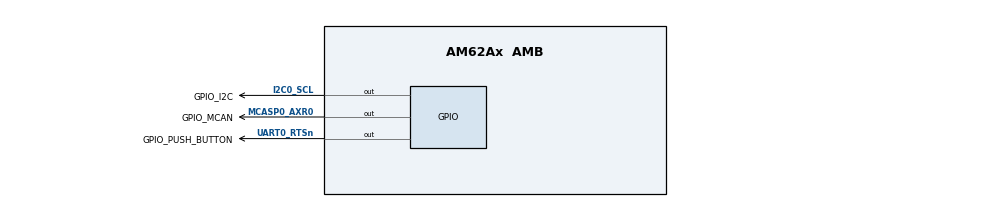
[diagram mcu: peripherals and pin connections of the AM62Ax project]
/**
 * @cliArgs --device "AM62Ax" --part "Default" --package "AMB" --context "mcu-r5fss0-0" --product "MCU_PLUS_SDK@07.03.01"
 * @versions {"tool":"1.26.2+4477"}
 */

/**
 * Import the modules used in this configuration.
 */
const gpio       = scripting.addModule("/drivers/gpio/gpio", {}, false);
const gpio1      = gpio.addInstance();
const gpio2      = gpio.addInstance();
const gpio3      = gpio.addInstance();
const gpio4      = gpio.addInstance();
const gpio5      = gpio.addInstance();
const gpio6      = gpio.addInstance();
const gpio7      = gpio.addInstance();
const gpio8      = gpio.addInstance();
const gpio9      = gpio.addInstance();
const gpio10     = gpio.addInstance();
const debug_log  = scripting.addModule("/kernel/dpl/debug_log");
const mpu_armv7  = scripting.addModule("/kernel/dpl/mpu_armv7", {}, false);
const mpu_armv71 = mpu_armv7.addInstance();
const mpu_armv72 = mpu_armv7.addInstance();
const mpu_armv73 = mpu_armv7.addInstance();
const mpu_armv74 = mpu_armv7.addInstance();
const mpu_armv75 = mpu_armv7.addInstance();
const mpu_armv76 = mpu_armv7.addInstance();

/**
 * Write custom configuration values to the imported modules.
 */
gpio1.$name  = "GPIO_LED";
gpio1.pinDir = "OUTPUT";

gpio2.$name                   = "GPIO_PUSH_BUTTON";
gpio2.trigType                = "RISE_EDGE";
gpio2.useMcuDomainPeripherals = false;
gpio2.GPIO.gpioPin.$assign    = "UART0_RTSn";

gpio3.$name                   = "GPIO_I2C";
gpio3.pinDir                  = "OUTPUT";
gpio3.trigType                = "FALL_EDGE";
gpio3.useMcuDomainPeripherals = false;
gpio3.GPIO.gpioPin.$assign    = "I2C0_SCL";

gpio4.$name                   = "GPIO_MCAN";
gpio4.pinDir                  = "OUTPUT";
gpio4.trigType                = "BOTH_EDGE";
gpio4.useMcuDomainPeripherals = false;
gpio4.GPIO.gpioPin.$assign    = "MCASP0_AXR0";

gpio5.$name    = "GPIO_OSPI_D1";
gpio5.pinDir   = "OUTPUT";
gpio5.trigType = "RISE_EDGE";

gpio6.$name    = "GPIO_OSPI_D2";
gpio6.pinDir   = "OUTPUT";
gpio6.trigType = "FALL_EDGE";

gpio7.$name    = "GPIO_INPUT";
gpio7.trigType = "RISE_EDGE";

gpio8.$name    = "GPIO_OUTPUT";
gpio8.pinDir   = "OUTPUT";
gpio8.trigType = "RISE_EDGE";

gpio9.$name = "CONFIG_GPIO0";

gpio10.$name = "CONFIG_GPIO1";

debug_log.enableUartLog = true;
debug_log.uartLog.$name = "CONFIG_UART0";

mpu_armv71.$name             = "CONFIG_MPU_REGION0";
mpu_armv71.size              = 31;
mpu_armv71.attributes        = "Device";
mpu_armv71.accessPermissions = "Supervisor RD+WR, User RD";
mpu_armv71.allowExecute      = false;

mpu_armv72.$name             = "CONFIG_MPU_REGION1";
mpu_armv72.size              = 15;
mpu_armv72.accessPermissions = "Supervisor RD+WR, User RD";

mpu_armv73.$name             = "CONFIG_MPU_REGION2";
mpu_armv73.baseAddr          = 0x41010000;
mpu_armv73.size              = 15;
mpu_armv73.accessPermissions = "Supervisor RD+WR, User RD";

mpu_armv74.$name             = "CONFIG_MPU_REGION3";
mpu_armv74.accessPermissions = "Supervisor RD+WR, User RD";
mpu_armv74.baseAddr          = 0x79100000;
mpu_armv74.size              = 19;

mpu_armv75.$name             = "CONFIG_MPU_REGION4";
mpu_armv75.baseAddr          = 0x60000000;
mpu_armv75.size              = 28;
mpu_armv75.accessPermissions = "Supervisor RD, User RD";

mpu_armv76.$name    = "CONFIG_MPU_REGION5";
mpu_armv76.baseAddr = 0x80000000;
mpu_armv76.size     = 31;

/**
 * Pinmux solution for unlocked pins/peripherals. This ensures that minor changes to the automatic solver in a future
 * version of the tool will not impact the pinmux you originally saw.  These lines can be completely deleted in order to
 * re-solve from scratch.
 */
gpio1.MCU_GPIO.$suggestSolution                 = "MCU_GPIO0";
gpio1.MCU_GPIO.gpioPin.$suggestSolution         = "MCU_UART0_RTSn";
gpio2.GPIO.$suggestSolution                     = "GPIO1";
gpio3.GPIO.$suggestSolution                     = "GPIO1";
gpio4.GPIO.$suggestSolution                     = "GPIO1";
gpio5.MCU_GPIO.$suggestSolution                 = "MCU_GPIO0";
gpio5.MCU_GPIO.gpioPin.$suggestSolution         = "MCU_UART0_CTSn";
gpio6.MCU_GPIO.$suggestSolution                 = "MCU_GPIO0";
gpio6.MCU_GPIO.gpioPin.$suggestSolution         = "MCU_SPI0_D1";
gpio7.MCU_GPIO.$suggestSolution                 = "MCU_GPIO0";
gpio7.MCU_GPIO.gpioPin.$suggestSolution         = "MCU_SPI0_D0";
gpio8.MCU_GPIO.$suggestSolution                 = "MCU_GPIO0";
gpio8.MCU_GPIO.gpioPin.$suggestSolution         = "MCU_SPI0_CLK";
gpio9.MCU_GPIO.$suggestSolution                 = "MCU_GPIO0";
gpio9.MCU_GPIO.gpioPin.$suggestSolution         = "MCU_SPI0_CS1";
gpio10.MCU_GPIO.$suggestSolution                = "MCU_GPIO0";
gpio10.MCU_GPIO.gpioPin.$suggestSolution        = "MCU_SPI0_CS0";
debug_log.uartLog.MCU_UART.$suggestSolution     = "MCU_USART0";
debug_log.uartLog.MCU_UART.RXD.$suggestSolution = "MCU_UART0_RXD";
debug_log.uartLog.MCU_UART.TXD.$suggestSolution = "MCU_UART0_TXD";
